# ESP32-C5 register map
Vendor: ESPRESSIF SYSTEMS (SHANGHAI) CO., LTD.; Series: ESP32 C-Series; File version: 1
CPU: RV32IMAC r0p0, little endian, no MPU, no FPU, 0 interrupt priority bits
Address unit: 32 bits
Registers are 32-bit, read-write, reset 0x0 unless marked. A register's access mark holds for its fields unless they carry their own. Offsets are from the block's base; [hi:lo] are bit positions; {n}, {i} and the like mark numbered series.

## LP_ANA — LP_ANA Peripheral
Base 0x600B2C00
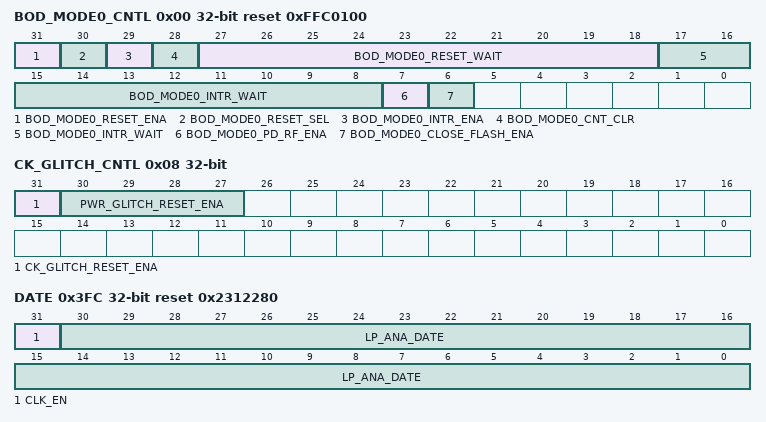
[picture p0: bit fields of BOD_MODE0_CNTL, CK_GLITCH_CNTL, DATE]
0x00 BOD_MODE0_CNTL reset 0xFFC0100 — Configure brownout mode0
  [31] BOD_MODE0_RESET_ENA — enable brownout reset or not 1: enable 0: disable
  [30] BOD_MODE0_RESET_SEL — select brownout reset level 1: system reset 0: chip reset
  [29] BOD_MODE0_INTR_ENA — enable brownout interrupt or not 1: enable 0: disable
  [28] BOD_MODE0_CNT_CLR — clear brownout count or not 1: clear 0: no operation
  [27:18] BOD_MODE0_RESET_WAIT — set the undervoltage hold time for triggering brownout reset
  [17:8] BOD_MODE0_INTR_WAIT — set the undervoltage hold time for triggering brownout interrupt
  [7] BOD_MODE0_PD_RF_ENA — enable power down RF when brownout interrupt or not 1:enable 0:disable
  [6] BOD_MODE0_CLOSE_FLASH_ENA — enable suspend spi when brownout interrupt or not 1:enable 0:disable
0x04 BOD_MODE1_CNTL — Configure brownout mode1
  [31] BOD_MODE1_RESET_ENA — enable brownout mode1 reset or not 1: enable 0: disable
0x08 CK_GLITCH_CNTL — Configure power glitch
  [31] CK_GLITCH_RESET_ENA — reserved
  [30:27] PWR_GLITCH_RESET_ENA — enable powerglitch or not
0x0C FIB_ENABLE reset 0xFFFFFFFF — configure FIB REG
  [31:0] ANA_FIB_ENA — configure analog fib by software
0x10 INT_RAW — interrpt raw register
  [31] BOD_MODE0_INT_RAW — brownout mode0 interrupt raw register
0x14 INT_ST ro — interrpt status register
  [31] BOD_MODE0_INT_ST — brownout mode0 interrupt status register
0x18 INT_ENA — interrpt enable register
  [31] BOD_MODE0_INT_ENA — brownout mode0 interrupt enable register
0x1C INT_CLR wo — interrpt clear register
  [31] BOD_MODE0_INT_CLR — brownout mode0 interrupt clear register
0x20 LP_INT_RAW — lp interrupt raw register
  [31] BOD_MODE0_LP_INT_RAW — brownout mode0 lp interrupt raw register
0x24 LP_INT_ST ro — lp interrupt status register
  [31] BOD_MODE0_LP_INT_ST — brownout mode0 lp interrupt status register
0x28 LP_INT_ENA — lp interrupt enable register
  [31] BOD_MODE0_LP_INT_ENA — brownout mode0 lp interrupt enable register
0x2C LP_INT_CLR wo — lp interrupt clear register
  [31] BOD_MODE0_LP_INT_CLR — brownout mode0 lp interrupt clear register
0x3FC DATE reset 0x2312280 — version register
  [31] CLK_EN — reserved
  [30:0] LP_ANA_DATE — version register

## LP_APM0 — LP_APM0 Peripheral
Base 0x600B3800
0x00 REGION_FILTER_EN reset 0x1 — Region filter enable register
  [3:0] REGION_FILTER_EN — Configure bit 0 (0-3) to enable region 0.\\ 0: disable \\ 1: enable \\
{0x4+0xC*i} REGION{i}_ADDR_START (i=0..3) — Region address register
  [31:0] REGION_ADDR_START — Configures start address of region %s.
{0x8+0xC*i} REGION{i}_ADDR_END (i=0..3) reset 0xFFFFFFFF — Region address register
  [31:0] REGION_ADDR_END — Configures end address of region %s.
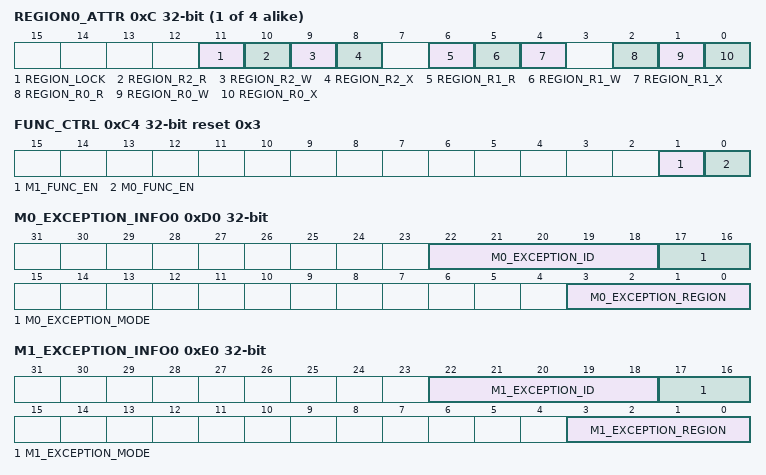
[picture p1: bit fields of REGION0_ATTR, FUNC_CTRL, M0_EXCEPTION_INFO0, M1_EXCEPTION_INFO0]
{0xC+0xC*i} REGION{i}_ATTR (i=0..3) — Region access authority attribute register
  [11] REGION_LOCK — Set 1 to lock region0 configuration
  [10] REGION_R2_R — Configures the read authority of REE_MODE 2 in region %s.
  [9] REGION_R2_W — Configures the write authority of REE_MODE 2 in region %s.
  [8] REGION_R2_X — Configures the execution authority of REE_MODE 2 in region %s.
  [6] REGION_R1_R — Configures the read authority of REE_MODE 1 in region %s.
  [5] REGION_R1_W — Configures the write authority of REE_MODE 1 in region %s.
  [4] REGION_R1_X — Configures the execution authority of REE_MODE 1 in region %s.
  [2] REGION_R0_R — Configures the read authority of REE_MODE 0 in region %s.
  [1] REGION_R0_W — Configures the write authority of REE_MODE 0 in region %s.
  [0] REGION_R0_X — Configures the execution authority of REE_MODE 0 in region %s.
0xC4 FUNC_CTRL reset 0x3 — APM function control register
  [1] M1_FUNC_EN — PMS M1 function enable
  [0] M0_FUNC_EN — PMS M0 function enable
0xC8 M0_STATUS ro
  [1:0] M0_EXCEPTION_STATUS — Represents exception status.\\ bit0: 1 represents authority_exception \\ bit1: 1 represents space_exception \\
0xCC M0_STATUS_CLR wo — M0 status clear register
  [0] M0_EXCEPTION_STATUS_CLR — Configures to clear exception status.
0xD0 M0_EXCEPTION_INFO0 ro
  [22:18] M0_EXCEPTION_ID — Represents exception id information.
  [17:16] M0_EXCEPTION_MODE — Represents exception mode.
  [3:0] M0_EXCEPTION_REGION — Represents exception region.
0xD4 M0_EXCEPTION_INFO1 ro
  [31:0] M0_EXCEPTION_ADDR — Represents exception addr.
0xD8 M1_STATUS ro
  [1:0] M1_EXCEPTION_STATUS — Represents exception status.\\ bit0: 1 represents authority_exception \\ bit1: 1 represents space_exception \\
0xDC M1_STATUS_CLR wo — M1 status clear register
  [0] M1_EXCEPTION_STATUS_CLR — Configures to clear exception status.
0xE0 M1_EXCEPTION_INFO0 ro
  [22:18] M1_EXCEPTION_ID — Represents exception id information.
  [17:16] M1_EXCEPTION_MODE — Represents exception mode.
  [3:0] M1_EXCEPTION_REGION — Represents exception region.
0xE4 M1_EXCEPTION_INFO1 ro
  [31:0] M1_EXCEPTION_ADDR — Represents exception addr.
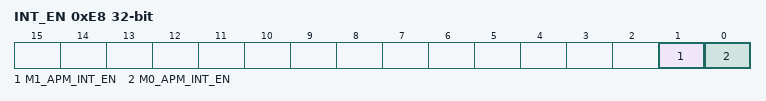
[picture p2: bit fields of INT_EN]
0xE8 INT_EN — APM interrupt enable register
  [1] M1_APM_INT_EN — Configures to enable APM M1 interrupt.\\ 0: disable \\ 1: enable \\
  [0] M0_APM_INT_EN — Configures to enable APM M0 interrupt.\\ 0: disable \\ 1: enable \\
0xEC CLOCK_GATE reset 0x1 — clock gating register
  [0] CLK_EN — Configures whether to keep the clock always on.\\ 0: enable automatic clock gating \\ 1: keep the clock always on \\
0xFC DATE reset 0x2212160 — Version control register
  [27:0] DATE — Version control register.
